# A34L71x register map
Vendor: ABOV Semiconductor Co., Ltd.; File version: 1.0
CPU: CM4 r0p1, little endian, MPU, FPU, VTOR, 4 interrupt priority bits
Registers are 32-bit, read-write, reset 0x0 unless marked. A register's access mark holds for its fields unless they carry their own. Offsets are from the block's base; [hi:lo] are bit positions; {n}, {i} and the like mark numbered series.

## USB — Universal Serial Bus 1.1
Base 0x41006000
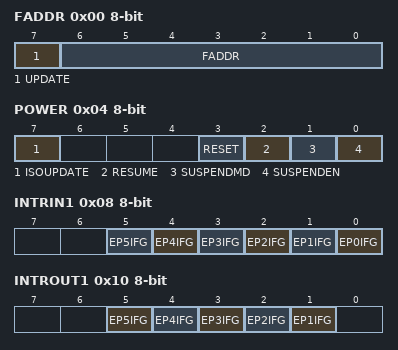
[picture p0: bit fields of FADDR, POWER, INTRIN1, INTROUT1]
0x00 FADDR 8-bit — Function Address register
  [7] UPDATE ro — Set when FADR is written. Cleared when the new address takes effect (at the end of the current transfer).
  [6:0] FADDR — The function address
0x04 POWER 8-bit — Power management register
  [7] ISOUPDATE — When set by the CPU, this Device will wait for an SOF token from the time InPktRdy is set before sending the packet. If an IN token is received before an SOF token, then a zero length data packet will be sent. This bit is only used by endpoints performing Isochronous transfers.
  [3] RESET ro — set while reset signaling is present on the bus
  [2] RESUME — Set by the cpu to generate resume signaling when the function is in suspend mode.
  [1] SUSPENDMD ro — Set by the USB when suspend mode is entered.
  [0] SUSPENDEN — Set by the CPU to enable entry into suspend mode when suspend signaling is received on the bus
0x08 INTRIN1 8-bit ro — Interrupt Flag Register for Endpoint 0 plus IN Endpoints 1 to 5
  [n] EP{n}IFG (n=0..5) — IN Endpoint {n} interrupt
0x10 INTROUT1 8-bit ro — Interrupt Flag Register for OUT Endpoints 1 to 5
  [n] EP{n}IFG (n=1..5) — OUT Endpoint {n} interrupt
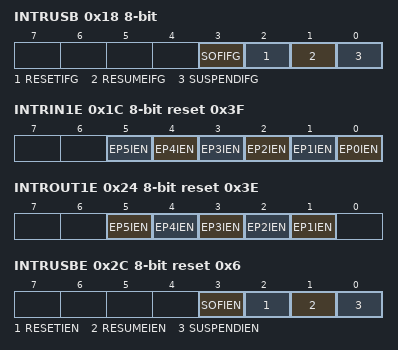
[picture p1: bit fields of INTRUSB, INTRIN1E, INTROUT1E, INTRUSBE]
0x18 INTRUSB 8-bit ro — Interrupt Enable Register for Common USB Interrupts
  [3] SOFIFG — Set at the start of each frame
  [2] RESETIFG — Set when reset signaling is detected on the bus
  [1] RESUMEIFG — Set when resume signaling is detected on the bus while the this Device is in suspend mode
  [0] SUSPENDIFG — Set when suspend signaling is detected on the bus.
0x1C INTRIN1E 8-bit reset 0x3F — Interrupt Enable Register for Endpoint 0 plus IN Endpoints 1 to 5
  [n] EP{n}IEN (n=0..5) — Interrupt enable for EP{n} IN
0x24 INTROUT1E 8-bit reset 0x3E — Interrupt Enable Register for OUT Endpoints 1 to 5
  [n] EP{n}IEN (n=1..5) — Interrupt enable for EP{n} OUT
0x2C INTRUSBE 8-bit reset 0x6 — Interrupt Enable Register for Common USB Interrupts
  [3] SOFIEN — Interrupt Enable for SOF
  [2] RESETIEN — Interrupt Enable for Reset
  [1] RESUMEIEN — Interrupt Enable for Resume
  [0] SUSPENDIEN — Interrupt Enable for Suspend
0x30 FRAME1 8-bit ro — Frame number bit 0 to 7
  [7:0] FRMNO — Lower 8 bits of Frame Number
0x34 FRAME2 8-bit ro — Frame number bit 8 to 10
  [2:0] FRMNO — Upper 3 bits of Frame Number
0x38 INDEX 8-bit — Index Register for Selecting the Endpoint Status and Control Registers
  [3:0] INDEX — Selected Endpoint
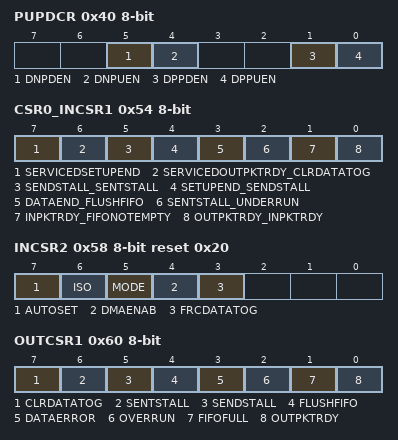
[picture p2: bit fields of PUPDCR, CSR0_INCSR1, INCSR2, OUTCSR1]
0x40 PUPDCR 8-bit — DP/DN Pins Pull-up/Down Resistor Control Register
  [5] DNPDEN — DN Pin Pull-down resistor enable bit
  [4] DNPUEN — DN Pin Pull-up resistor enable bit
  [1] DPPDEN — DP Pin Pull-down resistor enable bit
  [0] DPPUEN — DP Pin Pull-up resistor enable bit
0x44 PHYCR 8-bit reset 0x1 — USB Power control register
  [0] PHYSUSP_MODE — USB PHY IP changed suspend mode
0x50 INMAXP 8-bit — Maximum Packet Size for IN Endpoint. (Index Register set to select Endpoints 1 5 only)
  [7:0] INMAXPS — Maximum Packet Size / transaction for IN endpoint. 8 bytes unit. (ex. 0x04 = 32bytes, but 0x80 = 1023 bytes)
0x54 CSR0_INCSR1 8-bit — Control Status Register for Endpoint 0. (Index Register set to select Endpoint 0), Control Status Register 1 for IN Endpoint. (Index Register set to select Endpoints 1 5)
  [7] SERVICEDSETUPEND — Clear the SetupEnd bit.(Index Register set to select Endpoint 0),
  [6] SERVICEDOUTPKTRDY_CLRDATATOG — Clear the OutPktRdy bit.(Index Register set to select Endpoint 0), Reset the endpoint IN data toggle to 0(Index Register set to select Endpoints 1 5)
  [5] SENDSTALL_SENTSTALL — set to terminate the current transaction(Index Register set to select Endpoint 0), Detect when a STALL handshake is transmitted. The FIFO is flushed and the InPktRdy bit is cleared. The CPU should clear this bit.(Index Register set to select Endpoints 1 5)
  [4] SETUPEND_SENDSTALL — Detected when a control transaction ends before the DataEnd bit has been set. An interrupt will be generated and the FIFO flushed at this time.(Index Register set to select Endpoint 0), Set to issue a STALL handshake to an IN token. The CPU clears this bit to terminate the stall condition. This bit has no effect if the IN endpoint is in ISO mode.(Index Register set to select Endpoints 1 5)
  [3] DATAEND_FLUSHFIFO — The CPU sets this bit when : 1.setting InPktRdy for the last data packet 2.clearing OutPktRdy after unloading the last data packet 3.setting InPktRdy for a zero length data packet (Index Register set to select Endpoint 0), Set to flush the next packet to be transmitted from the endpoint IN FIFO. The FIFO pointer is reset and the InPktRdy bit is cleared. Note : If the FIFO contains two packets, FlushFIFO will need to be set twice to completely clear the FIFO..(Index Register set to select Endpoints 1 5)
  [2] SENTSTALL_UNDERRUN — Set when a STALL handshake is transmitted. The CPU should clear tis bit.(Index Register set to select Endpoint 0), In ISO mode, this bit is set when a zero length data packet is sent after receiving an IN token with the InPktRdy bit not set. In Bulk/Interrupt mode, this bit is set when a NAK is returned in response to an IN token. The CPU should clear this bit.(Index Register set to select Endpoints 1 5)
  [1] INPKTRDY_FIFONOTEMPTY — set after loading a data packet into the FIFO. An interrupt is generated when the bit is cleared.(Index Register set to select Endpoint 0), This bit is set when there is a lease 1 packet in the IN FIFO.(Index Register set to select Endpoints 1 5)
  [0] OUTPKTRDY_INPKTRDY — This bit is set when a data packet has been received. An interrupt is generated when this bit is set.(Index Register set to select Endpoint 0), Set after loading a data packet into the FIFO. It is cleared automatically when a data packet has been transmitted. An interrupt is generated (if enabled) when the bit is cleared.(Index Register set to select Endpoints 1 5)
0x58 INCSR2 8-bit reset 0x20 — Control Status Register 2 for IN Endpoint. (Index Register set to select Endpoints 1 5 only)
  [7] AUTOSET — If the CPU set this bit, InPktRdy will be automatically set when data of the maximum packet size (value in InMaxP) is loaded into the IN FIFO. If a packet of less than the maximum packet size is loaded, then InPktRdy will have to be set manually.
  [6] ISO — Enable the IN endpoint for isochronous transfers (ISO mode), and clears it to enable the IN endpoint for bulk/interrupt transfers.
  [5] MODE — Set the endpoint direction. Valid only when the same endpoint FIFO is used for both IN and OUT transactions.
  [4] DMAENAB — Set to enable the DMA request for the IN endpoint.
  [3] FRCDATATOG — Set to force the endpoints IN data toggle to switch after each data packet is sent regardless of whether an ACK was received. This can be used by interrupt IN endpoints which are used to communicated rate feedback for Isochronous endpoints.
0x5C OUTMAXP 8-bit — Maximum Packet Size for OUT Endpoint. (Index Register set to select Endpoints 1 5 only)
  [7:0] OUTMAXPS — Maximum Packet Size / transaction
0x60 OUTCSR1 8-bit — Control Status Register 1 for OUT Endpoint. (Index Register set to select Endpoints 1 5 only)
  [7] CLRDATATOG — Reset the Endpoint data toggle to 0
  [6] SENTSTALL — Detect STALL handshake
  [5] SENDSTALL — Issue a STALL handshake. Ignored in ISO mode
  [4] FLUSHFIFO — Flush the next packet to be read from the endpoint OUT FIFO. Note : if the FIFO contains two packets, FlushFIFO will need to be set twice to completely clear the FIFO
  [3] DATAERROR — Set when OutPktRdy is set if the data packet has a CRC or bit-stuff error. This bit is only valid in ISO mode.
  [2] OVERRUN — Set if an OUT packet cannot be loaded into the OUT FIFO. The CPU should clear this bit. The bit is only valid is ISO mode
  [1] FIFOFULL — Set when no more packets can be loaded into the OUT FIFO
  [0] OUTPKTRDY — Set when a data packet has been received. The CPU should clear this bit when the packet has been unloaded from the OUT FIFO. An interrupt is generated when the bit is set.
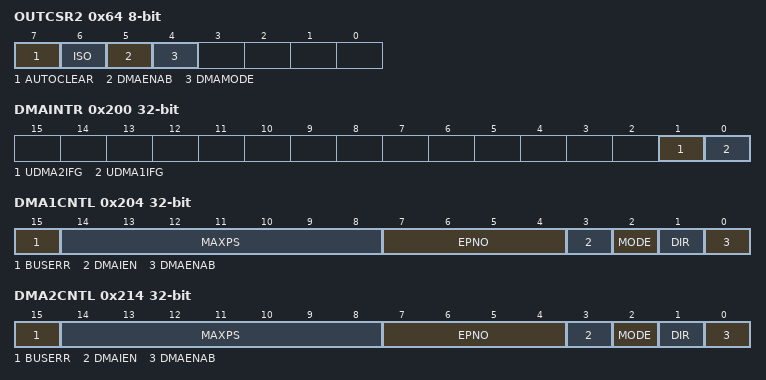
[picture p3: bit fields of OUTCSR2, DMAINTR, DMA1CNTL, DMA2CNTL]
0x64 OUTCSR2 8-bit — Control Status Register 2 for OUT Endpoint. (Index Register set to select Endpoints 1 5 only)
  [7] AUTOCLEAR — If the CPU set this bit then the OutPktRdy bit will be automatically cleared when a packet of OutMaxP bytes has been unloaded from the OUT FIFO. When packets of less than the maximum packet size are unloaded, OutPktRdy will have to be cleared manually.
  [6] ISO — Enable the OUT endpoint for Isochronous transfers, and clears it to enable the OUT endpoint for Bulk/Interrupt transfers.
  [5] DMAENAB — Enable the DMA request for the OUT endpoints
  [4] DMAMODE — Two modes of DMA operation are supported like below. DMA mode 0 in which a DMA request is generated for all received packets, together with an interrupt (if enabled). DMA mode 1 in which a DMA request (but no interrupt) is generated for OUT packets of size OutMaxP bytes and an interrupt (but no DMA request) is generated for OUT packets of any other size.
0x68 COUNT0_OUTCOUNT1 8-bit ro — Number of Received Bytes in Endpoint 0 FIFO. (Index Register set to select Endpoint 0) Number of Bytes in OUT Endpoint FIFO (Lower Byte). (Index register set to select Endpoints 1 5 only)
  [7:0] EP0OUTCNT_EPOUTCNT — Endpoint 0 Out Count(Index Register set to select Endpoint 0) Endpoint OUT count lower 8 bits(Index register set to select Endpoints 1 5 only)
0x6C OUTCOUNT2 8-bit ro — Number of Bytes in OUT Endpoint FIFO (Upper Byte). (Index Register set to select Endpoints 1 5 only)
  [2:0] EPOUTCNT — Endpoint OUT count upper 3bits
{0x80+0x10*i} FIFO_EP{i} (i=0..5) — FIFO for EP{i}
  [7:0] FIFO_EP — IN/OUT FIFO for each endpoint
0x200 DMAINTR ro — USB DMA Interrupt Pending Register
  [1] UDMA2IFG — USB DMA 2 Interrupt flag bit
  [0] UDMA1IFG — USB DMA 1 Interrupt flag bit
0x204 DMA1CNTL — USB DMA Channel 1 Control Register
  [15] BUSERR ro — BUS Error bit
  [14:8] MAXPS — DMA 1 Maximum Packet Size in units of 8 bytes. Required for Mode 1 only
  [7:4] EPNO — DMA 1 Endpoint Number bits
  [3] DMAIEN — DMA 1 Interrupt Enable bit
  [2] MODE — DMA 1 Mode Select bit
  [1] DIR — DMA 1 Transfer Direction Select bit
  [0] DMAENAB — DMA 1 Enable bit
0x208 DMA1ADDR — USB DMA Channel 1 Memory Address Register
  [31:0] ADDR — DMA Channel 1 Memory Address bits
0x20C DMA1COUNT — USB DMA Channel 1 Transfer Byte Count Register
  [31:0] TRSCNT — DMA Channel 1 Transfer Byte Count bits
0x214 DMA2CNTL — USB DMA Channel 2 Control Register
  [15] BUSERR ro — BUS Error bit
  [14:8] MAXPS — DMA 2 Maximum Packet Size in units of 8 bytes. Required for Mode 1 only
  [7:4] EPNO — DMA 2 Endpoint Number bits
  [3] DMAIEN — DMA 2 Interrupt Enable bit
  [2] MODE — DMA 2 Mode Select bit
  [1] DIR — DMA 2 Transfer Direction Select bit
  [0] DMAENAB — DMA 2 Enable bit
0x218 DMA2ADDR — USB DMA Channel 2 Memory Address Register
  [31:0] ADDR — DMA Channel 2 Memory Address bits
0x21C DMA2COUNT — USB DMA Channel 2 Transfer Byte Count Register
  [31:0] TRSCNT — DMA Channel 2 Transfer Byte Count bits
